VERSION ""

NS_ :

BS_:

BU_: XXX

BO_ 177 FRONT_WHEEL: 6 XXX
 SG_ FRONT_RIGHT_WHEEL : 7|16@0+ (0.01,0) [0|65535] "km/h" XXX
 SG_ FRONT_LEFT_WHEEL : 23|16@0+ (0.01,0) [0|65535] "" XXX

BO_ 37 NEW_MSG_1: 8 XXX
 SG_ NEW_SIGNAL_1 : 7|16@0+ (1,0) [0|65535] "" XXX

BO_ 179 REAR_WHEEL: 6 XXX
 SG_ REAR_LEFT_WHEEL : 23|16@0+ (1,0) [0|65535] "" XXX

BO_ 970 SPEED: 5 XXX
 SG_ SPEED : 23|8@0+ (1,0) [0|255] "" XXX

BO_ 973 BATTERY: 5 XXX
 SG_ PACK_VOLTAGE : 23|16@0+ (1,0) [0|65535] "" XXX

BO_ 1324 COOLANT_TEMP: 2 XXX
 SG_ ENGINE_COOLANT_TEMP : 15|8@0+ (0.5,0) [0|255] "" XXX

BO_ 59 BATTERY: 8 XXX
 SG_ BATTERY_CURRENT : 3|12@0- (0.1,0) [-240|240] "A" XXX
 SG_ BATTERY_VOLTAGE : 23|16@0+ (1,0) [0|65535] "V" XXX

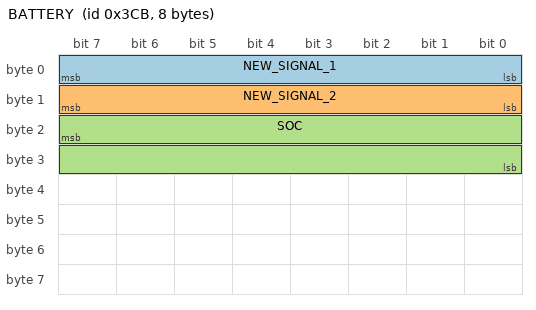
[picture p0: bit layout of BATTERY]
BO_ 971 BATTERY: 8 XXX
 SG_ NEW_SIGNAL_1 : 7|8@0+ (1,0) [0|255] "" XXX
 SG_ NEW_SIGNAL_2 : 15|8@0+ (1,0) [0|255] "" XXX
 SG_ SOC : 23|16@0+ (0.5,0) [0|65535] "" XXX

CM_ SG_ 59 BATTERY_CURRENT "positive values are discharge, negative are charge";
